# ATSAMD51J20A device description
Architecture: CORTEX-M4; Family: SAMD; Series: SAMD51
Registers are 32-bit, read-write, reset 0x0 unless marked. A register's access mark holds for its fields unless they carry their own. Offsets are from the block's base; [hi:lo] are bit positions; 'fields as' and 'values as' point back to an identical list.

## SW0_FUSES — Non-Volatile Fuses
Instances: SW0_FUSES 0x00800080 in fuses
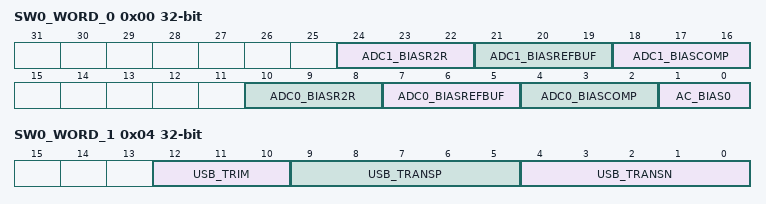
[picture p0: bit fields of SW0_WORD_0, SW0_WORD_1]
0x00 SW0_WORD_0 ro reset not defined — SW0 Page Word 0
  [24:22] ADC1_BIASR2R — ADC Bias R2R ampli scaling
  [21:19] ADC1_BIASREFBUF — ADC Bias Reference Buffer Scaling
  [18:16] ADC1_BIASCOMP — ADC Comparator Scaling
  [10:8] ADC0_BIASR2R — ADC Bias R2R ampli scaling
  [7:5] ADC0_BIASREFBUF — ADC Bias Reference Buffer Scaling
  [4:2] ADC0_BIASCOMP — ADC Comparator Scaling
  [1:0] AC_BIAS0 — PAIR0 Bias Calibration
0x04 SW0_WORD_1 ro reset not defined — SW0 Page Word 1
  [12:10] USB_TRIM — USB pad Trim calibration
  [9:5] USB_TRANSP — USB pad Transp calibration
  [4:0] USB_TRANSN — USB pad Transn calibration

## TEMP_LOG_FUSES — Non-Volatile Fuses
Instances: TEMP_LOG_FUSES 0x00800100 in fuses
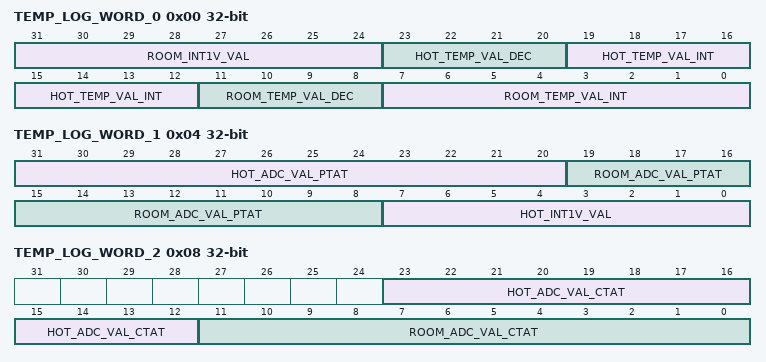
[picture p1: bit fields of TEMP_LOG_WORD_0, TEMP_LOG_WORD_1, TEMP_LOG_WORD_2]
0x00 TEMP_LOG_WORD_0 ro reset not defined — TEMP_LOG Page Word 0
  [31:24] ROOM_INT1V_VAL — 2's complement of the internal 1V reference drift at room temperature (versus a 1.0 centered value)
  [23:20] HOT_TEMP_VAL_DEC — Decimal part of hot temperature
  [19:12] HOT_TEMP_VAL_INT — Integer part of hot temperature in oC
  [11:8] ROOM_TEMP_VAL_DEC — Decimal part of room temperature
  [7:0] ROOM_TEMP_VAL_INT — Integer part of room temperature in oC
0x04 TEMP_LOG_WORD_1 ro reset not defined — TEMP_LOG Page Word 1
  [31:20] HOT_ADC_VAL_PTAT — 12-bit ADC conversion at hot temperature PTAT
  [19:8] ROOM_ADC_VAL_PTAT — 12-bit ADC conversion at room temperature PTAT
  [7:0] HOT_INT1V_VAL — 2's complement of the internal 1V reference drift at hot temperature (versus a 1.0 centered value)
0x08 TEMP_LOG_WORD_2 ro reset not defined — TEMP_LOG Page Word 2
  [23:12] HOT_ADC_VAL_CTAT — 12-bit ADC conversion at hot temperature CTAT
  [11:0] ROOM_ADC_VAL_CTAT — 12-bit ADC conversion at room temperature CTAT

## USER_FUSES — Non-Volatile Fuses
Instances: USER_FUSES 0x00804000 in fuses
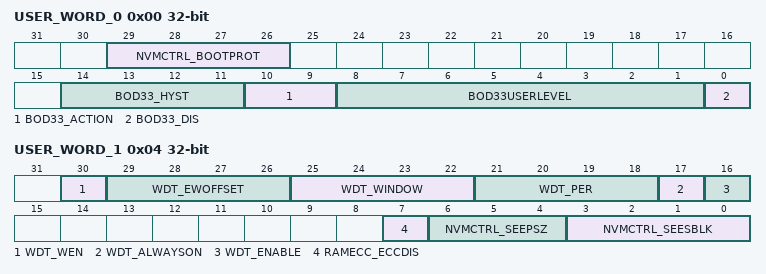
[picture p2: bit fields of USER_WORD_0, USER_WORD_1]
0x00 USER_WORD_0 reset not defined — USER Page Word 0
  [29:26] NVMCTRL_BOOTPROT — Bootloader Size
    15=0 kbytes; 14=8 kbytes; 13=16 kbytes; 12=24 kbytes; 11=32 kbytes; 10=40 kbytes; 9=48 kbytes; 8=56 kbytes; 7=64 kbytes; 6=72 kbytes; 5=80 kbytes; 4=88 kbytes; 3=96 kbytes; 2=104 kbytes; 1=112 kbytes; 0=120 kbytes
  [14:11] BOD33_HYST — BOD33 Hysteresis
  [10:9] BOD33_ACTION
    0=NONE (No action); 1=RESET (The BOD33 generates a reset); 2=INT (The BOD33 generates an interrupt); 3=BKUP (The BOD33 puts the device in backup sleep mode)
  [8:1] BOD33USERLEVEL
  [0] BOD33_DIS — BOD33 Disable
0x04 USER_WORD_1 reset not defined — USER Page Word 1
  [30] WDT_WEN — WDT Window Mode Enable
  [29:26] WDT_EWOFFSET — WDT Early Warning Offset
    0=CYC8 (8 clock cycles); 1=CYC16 (16 clock cycles); 2=CYC32 (32 clock cycles); 3=CYC64 (64 clock cycles); 4=CYC128 (128 clock cycles); 5=CYC256 (256 clock cycles); 6=CYC512 (512 clock cycles); 7=CYC1024 (1024 clock cycles); 8=CYC2048 (2048 clock cycles); 9=CYC4096 (4096 clock cycles); 10=CYC8192 (8192 clock cycles); 11=CYC16384 (16384 clock cycles)
  [25:22] WDT_WINDOW
    values as WDT_EWOFFSET
  [21:18] WDT_PER — WDT Period
    values as WDT_EWOFFSET
  [17] WDT_ALWAYSON
  [16] WDT_ENABLE
  [7] RAMECC_ECCDIS — RAM ECC Disable fuse
  [6:4] NVMCTRL_SEEPSZ — Size Of SmartEEPROM Page
  [3:0] NVMCTRL_SEESBLK — Number Of Physical NVM Blocks Composing a SmartEEPROM Sector
0x08 USER_WORD_2 reset not defined — USER Page Word 2
  [31:0] NVMCTRL_REGION_LOCKS — NVM Region Locks

## OSC32KCTRL — 32kHz Oscillators Control
Instances: OSC32KCTRL 0x40001400
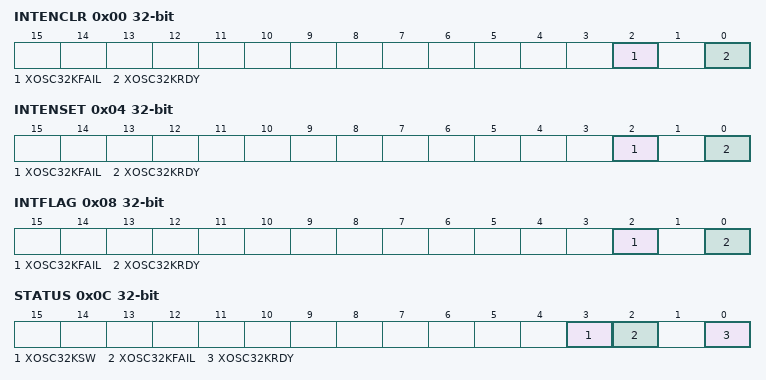
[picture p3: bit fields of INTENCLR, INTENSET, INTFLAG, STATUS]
0x00 INTENCLR (atomic clear) — Interrupt Enable Clear
  [2] XOSC32KFAIL — XOSC32K Clock Failure Detector Interrupt Enable
  [0] XOSC32KRDY — XOSC32K Ready Interrupt Enable
0x04 INTENSET (atomic set) — Interrupt Enable Set
  fields as INTENCLR
0x08 INTFLAG (atomic clear) — Interrupt Flag Status and Clear
  [2] XOSC32KFAIL — XOSC32K Clock Failure Detector
  [0] XOSC32KRDY — XOSC32K Ready
0x0C STATUS ro — Power and Clocks Status
  [3] XOSC32KSW — XOSC32K Clock switch
  [2] XOSC32KFAIL — XOSC32K Clock Failure Detector
  [0] XOSC32KRDY — XOSC32K Ready
0x10 RTCCTRL 8-bit — RTC Clock Selection
  [2:0] RTCSEL
    0=ULP1K (1.024kHz from 32kHz internal ULP oscillator); 1=ULP32K (32.768kHz from 32kHz internal ULP oscillator); 4=XOSC1K (1.024kHz from 32.768kHz internal oscillator); 5=XOSC32K (32.768kHz from 32.768kHz external crystal oscillator)
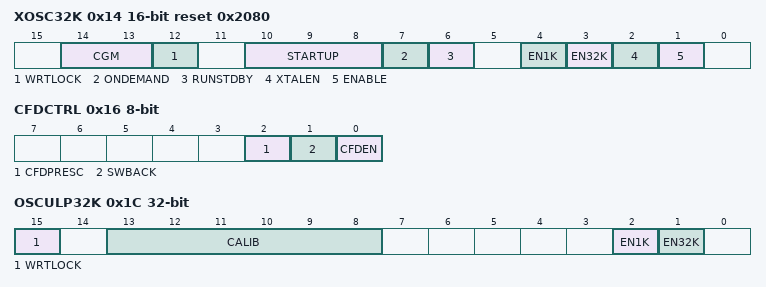
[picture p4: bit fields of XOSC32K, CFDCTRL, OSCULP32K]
0x14 XOSC32K 16-bit reset 0x2080 — 32kHz External Crystal Oscillator (XOSC32K) Control
  [14:13] CGM — Control Gain Mode
    1=XT (Standard mode); 2=HS (High Speed mode)
  [12] WRTLOCK — Write Lock
  [10:8] STARTUP — Oscillator Start-Up Time
    0=CYCLE2048 (62.6 ms); 1=CYCLE4096 (125 ms); 2=CYCLE16384 (500 ms); 3=CYCLE32768 (1000 ms); 4=CYCLE65536 (2000 ms); 5=CYCLE131072 (4000 ms); 6=CYCLE262144 (8000 ms)
  [7] ONDEMAND — On Demand Control
  [6] RUNSTDBY — Run in Standby
  [4] EN1K — 1kHz Output Enable
  [3] EN32K — 32kHz Output Enable
  [2] XTALEN — Crystal Oscillator Enable
  [1] ENABLE — Oscillator Enable
0x16 CFDCTRL 8-bit — Clock Failure Detector Control
  [2] CFDPRESC — Clock Failure Detector Prescaler
  [1] SWBACK — Clock Switch Back
  [0] CFDEN — Clock Failure Detector Enable
0x17 EVCTRL 8-bit — Event Control
  [0] CFDEO — Clock Failure Detector Event Output Enable
0x1C OSCULP32K — 32kHz Ultra Low Power Internal Oscillator (OSCULP32K) Control
  [15] WRTLOCK — Write Lock
  [13:8] CALIB — Oscillator Calibration
  [2] EN1K — Enable Out 1k
  [1] EN32K — Enable Out 32k
